# control_module register map
Vendor: Texas Instruments
Registers are 32-bit, access per field, no defined reset value unless marked. A register's access mark holds for its fields unless they carry their own. Offsets are as the file gives them; [hi:lo] are bit positions; 'fields as' and 'values as' point back to an identical list.

## CONTROL_MODULE (part 2 of 3)
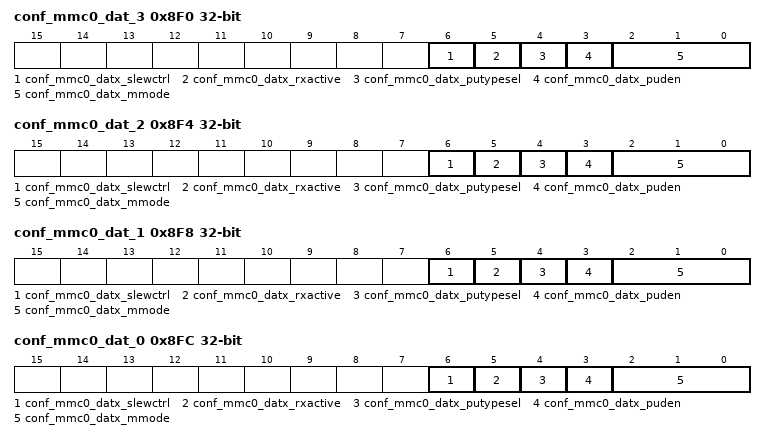
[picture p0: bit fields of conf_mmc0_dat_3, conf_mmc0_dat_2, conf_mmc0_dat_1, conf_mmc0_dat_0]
0x8F0 conf_mmc0_dat_3 — See the device datasheet for information on default pin mux configurations. Note that the device ROM may change the default pin mux for certain pins based on the SYSBOOT mode settings.
  [6] conf_mmc0_datx_slewctrl rw — Select between faster or slower slew rate Reset value is pad-dependent.
    1=en_2_0x1 (Slow); 0=en_1_0x0 (Fast)
  [5] conf_mmc0_datx_rxactive rw — Input enable value for the PAD
    1=en_2_0x1 (Receiver enabled); 0=en_1_0x0 (Receiver disabled)
  [4] conf_mmc0_datx_putypesel rw — Pad pullup/pulldown type selection Reset value is pad-dependent.
    1=en_2_0x1 (Pullup selected); 0=en_1_0x0 (Pulldown selected)
  [3] conf_mmc0_datx_puden rw — Pad pullup/pulldown enable Reset value is pad-dependent.
    1=en_2_0x1 (Pullup/pulldown disabled); 0=en_1_0x0 (Pullup/pulldown enabled)
  [2:0] conf_mmc0_datx_mmode rw — Pad functional signal mux select. Reset value is pad-dependent.
0x8F4 conf_mmc0_dat_2 — See the device datasheet for information on default pin mux configurations. Note that the device ROM may change the default pin mux for certain pins based on the SYSBOOT mode settings.
  fields as conf_mmc0_dat_3
0x8F8 conf_mmc0_dat_1 — See the device datasheet for information on default pin mux configurations. Note that the device ROM may change the default pin mux for certain pins based on the SYSBOOT mode settings.
  fields as conf_mmc0_dat_3
0x8FC conf_mmc0_dat_0 — See the device datasheet for information on default pin mux configurations. Note that the device ROM may change the default pin mux for certain pins based on the SYSBOOT mode settings.
  fields as conf_mmc0_dat_3
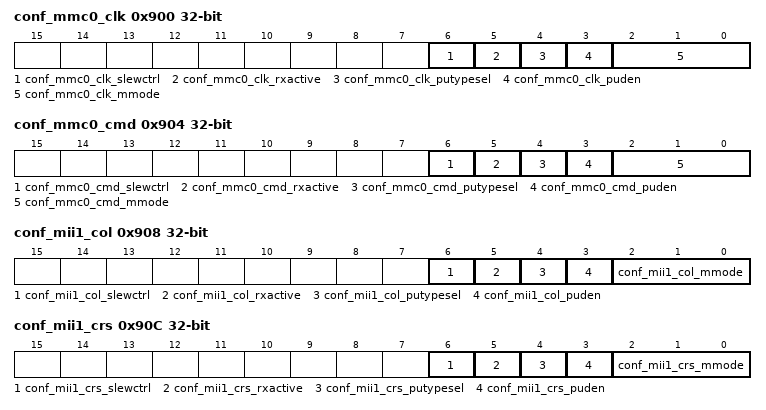
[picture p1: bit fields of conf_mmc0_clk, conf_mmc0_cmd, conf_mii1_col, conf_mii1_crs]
0x900 conf_mmc0_clk — See the device datasheet for information on default pin mux configurations. Note that the device ROM may change the default pin mux for certain pins based on the SYSBOOT mode settings.
  [6] conf_mmc0_clk_slewctrl rw — Select between faster or slower slew rate Reset value is pad-dependent.
    1=en_2_0x1 (Slow); 0=en_1_0x0 (Fast)
  [5] conf_mmc0_clk_rxactive rw — Input enable value for the PAD
    values as conf_mmc0_dat_3.conf_mmc0_datx_rxactive
  [4] conf_mmc0_clk_putypesel rw — Pad pullup/pulldown type selection Reset value is pad-dependent.
    1=en_2_0x1 (Pullup selected); 0=en_1_0x0 (Pulldown selected)
  [3] conf_mmc0_clk_puden rw — Pad pullup/pulldown enable Reset value is pad-dependent.
    values as conf_mmc0_dat_3.conf_mmc0_datx_puden
  [2:0] conf_mmc0_clk_mmode rw — Pad functional signal mux select. Reset value is pad-dependent.
0x904 conf_mmc0_cmd — See the device datasheet for information on default pin mux configurations. Note that the device ROM may change the default pin mux for certain pins based on the SYSBOOT mode settings.
  [6] conf_mmc0_cmd_slewctrl rw — Select between faster or slower slew rate Reset value is pad-dependent.
    1=en_2_0x1 (Slow); 0=en_1_0x0 (Fast)
  [5] conf_mmc0_cmd_rxactive rw — Input enable value for the PAD
    values as conf_mmc0_dat_3.conf_mmc0_datx_rxactive
  [4] conf_mmc0_cmd_putypesel rw — Pad pullup/pulldown type selection Reset value is pad-dependent.
    1=en_2_0x1 (Pullup selected); 0=en_1_0x0 (Pulldown selected)
  [3] conf_mmc0_cmd_puden rw — Pad pullup/pulldown enable Reset value is pad-dependent.
    values as conf_mmc0_dat_3.conf_mmc0_datx_puden
  [2:0] conf_mmc0_cmd_mmode rw — Pad functional signal mux select. Reset value is pad-dependent.
0x908 conf_mii1_col — See the device datasheet for information on default pin mux configurations. Note that the device ROM may change the default pin mux for certain pins based on the SYSBOOT mode settings.
  [6] conf_mii1_col_slewctrl rw — Select between faster or slower slew rate Reset value is pad-dependent.
    1=en_2_0x1 (Slow); 0=en_1_0x0 (Fast)
  [5] conf_mii1_col_rxactive rw — Input enable value for the PAD
    values as conf_mmc0_dat_3.conf_mmc0_datx_rxactive
  [4] conf_mii1_col_putypesel rw — Pad pullup/pulldown type selection Reset value is pad-dependent.
    1=en_2_0x1 (Pullup selected); 0=en_1_0x0 (Pulldown selected)
  [3] conf_mii1_col_puden rw — Pad pullup/pulldown enable Reset value is pad-dependent.
    values as conf_mmc0_dat_3.conf_mmc0_datx_puden
  [2:0] conf_mii1_col_mmode rw — Pad functional signal mux select. Reset value is pad-dependent.
0x90C conf_mii1_crs — See the device datasheet for information on default pin mux configurations. Note that the device ROM may change the default pin mux for certain pins based on the SYSBOOT mode settings.
  [6] conf_mii1_crs_slewctrl rw — Select between faster or slower slew rate Reset value is pad-dependent. Select between faster or slower slew rate Reset value is pad-dependent.
    1=en_2_0x1 (Slow); 0=en_1_0x0 (Fast)
  [5] conf_mii1_crs_rxactive rw — Input enable value for the PAD Input enable value for the PAD
    values as conf_mmc0_dat_3.conf_mmc0_datx_rxactive
  [4] conf_mii1_crs_putypesel rw — Pad pullup/pulldown type selection Reset value is pad-dependent. Pad pullup/pulldown type selection Reset value is pad-dependent.
    1=en_2_0x1 (Pullup selected); 0=en_1_0x0 (Pulldown selected)
  [3] conf_mii1_crs_puden rw — Pad pullup/pulldown enable Reset value is pad-dependent. Pad pullup/pulldown enable Reset value is pad-dependent.
    values as conf_mmc0_dat_3.conf_mmc0_datx_puden
  [2:0] conf_mii1_crs_mmode rw — Pad functional signal mux select. Reset value is pad-dependent. Pad functional signal mux select. Reset value is pad-dependent.
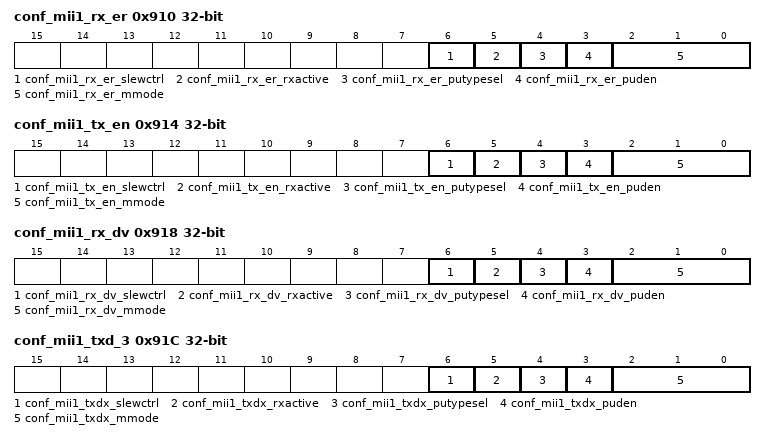
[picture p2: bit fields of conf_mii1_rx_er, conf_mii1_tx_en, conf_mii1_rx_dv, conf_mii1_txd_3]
0x910 conf_mii1_rx_er — See the device datasheet for information on default pin mux configurations. Note that the device ROM may change the default pin mux for certain pins based on the SYSBOOT mode settings.
  [6] conf_mii1_rx_er_slewctrl rw — Select between faster or slower slew rate Reset value is pad-dependent.
    1=en_2_0x1 (Slow); 0=en_1_0x0 (Fast)
  [5] conf_mii1_rx_er_rxactive rw — Input enable value for the PAD
    values as conf_mmc0_dat_3.conf_mmc0_datx_rxactive
  [4] conf_mii1_rx_er_putypesel rw — Pad pullup/pulldown type selection Reset value is pad-dependent.
    1=en_2_0x1 (Pullup selected); 0=en_1_0x0 (Pulldown selected)
  [3] conf_mii1_rx_er_puden rw — Pad pullup/pulldown enable Reset value is pad-dependent.
    values as conf_mmc0_dat_3.conf_mmc0_datx_puden
  [2:0] conf_mii1_rx_er_mmode rw — Pad functional signal mux select. Reset value is pad-dependent.
0x914 conf_mii1_tx_en — See the device datasheet for information on default pin mux configurations. Note that the device ROM may change the default pin mux for certain pins based on the SYSBOOT mode settings.
  [6] conf_mii1_tx_en_slewctrl rw — Select between faster or slower slew rate Reset value is pad-dependent.
    1=en_2_0x1 (Slow); 0=en_1_0x0 (Fast)
  [5] conf_mii1_tx_en_rxactive rw — Input enable value for the PAD
    values as conf_mmc0_dat_3.conf_mmc0_datx_rxactive
  [4] conf_mii1_tx_en_putypesel rw — Pad pullup/pulldown type selection Reset value is pad-dependent.
    1=en_2_0x1 (Pullup selected); 0=en_1_0x0 (Pulldown selected)
  [3] conf_mii1_tx_en_puden rw — Pad pullup/pulldown enable Reset value is pad-dependent.
    values as conf_mmc0_dat_3.conf_mmc0_datx_puden
  [2:0] conf_mii1_tx_en_mmode rw — Pad functional signal mux select. Reset value is pad-dependent.
0x918 conf_mii1_rx_dv — See the device datasheet for information on default pin mux configurations. Note that the device ROM may change the default pin mux for certain pins based on the SYSBOOT mode settings.
  [6] conf_mii1_rx_dv_slewctrl rw — Select between faster or slower slew rate Reset value is pad-dependent.
    1=en_2_0x1 (Slow); 0=en_1_0x0 (Fast)
  [5] conf_mii1_rx_dv_rxactive rw — Input enable value for the PAD
    values as conf_mmc0_dat_3.conf_mmc0_datx_rxactive
  [4] conf_mii1_rx_dv_putypesel rw — Pad pullup/pulldown type selection Reset value is pad-dependent.
    1=en_2_0x1 (Pullup selected); 0=en_1_0x0 (Pulldown selected)
  [3] conf_mii1_rx_dv_puden rw — Pad pullup/pulldown enable Reset value is pad-dependent.
    values as conf_mmc0_dat_3.conf_mmc0_datx_puden
  [2:0] conf_mii1_rx_dv_mmode rw — Pad functional signal mux select. Reset value is pad-dependent.
0x91C conf_mii1_txd_3 — See the device datasheet for information on default pin mux configurations. Note that the device ROM may change the default pin mux for certain pins based on the SYSBOOT mode settings.
  [6] conf_mii1_txdx_slewctrl rw — Select between faster or slower slew rate Reset value is pad-dependent.
    1=en_2_0x1 (Slow); 0=en_1_0x0 (Fast)
  [5] conf_mii1_txdx_rxactive rw — Input enable value for the PAD
    values as conf_mmc0_dat_3.conf_mmc0_datx_rxactive
  [4] conf_mii1_txdx_putypesel rw — Pad pullup/pulldown type selection Reset value is pad-dependent.
    1=en_2_0x1 (Pullup selected); 0=en_1_0x0 (Pulldown selected)
  [3] conf_mii1_txdx_puden rw — Pad pullup/pulldown enable Reset value is pad-dependent.
    values as conf_mmc0_dat_3.conf_mmc0_datx_puden
  [2:0] conf_mii1_txdx_mmode rw — Pad functional signal mux select. Reset value is pad-dependent.
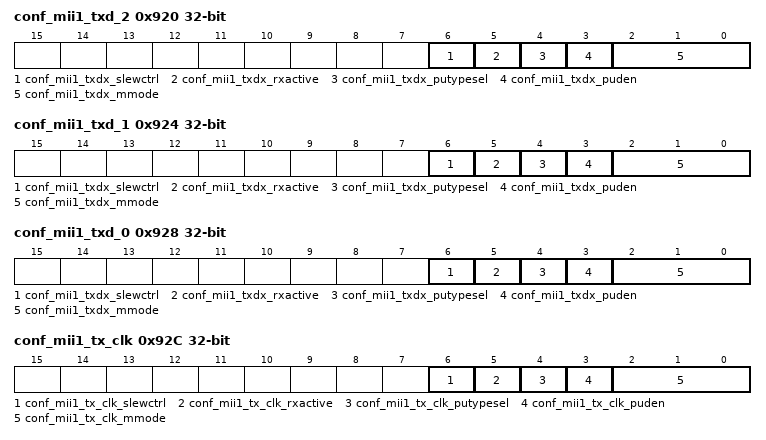
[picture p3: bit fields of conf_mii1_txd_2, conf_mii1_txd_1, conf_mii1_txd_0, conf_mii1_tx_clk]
0x920 conf_mii1_txd_2 — See the device datasheet for information on default pin mux configurations. Note that the device ROM may change the default pin mux for certain pins based on the SYSBOOT mode settings.
  fields as conf_mii1_txd_3
0x924 conf_mii1_txd_1 — See the device datasheet for information on default pin mux configurations. Note that the device ROM may change the default pin mux for certain pins based on the SYSBOOT mode settings.
  fields as conf_mii1_txd_3
0x928 conf_mii1_txd_0 — See the device datasheet for information on default pin mux configurations. Note that the device ROM may change the default pin mux for certain pins based on the SYSBOOT mode settings.
  fields as conf_mii1_txd_3
0x92C conf_mii1_tx_clk — See the device datasheet for information on default pin mux configurations. Note that the device ROM may change the default pin mux for certain pins based on the SYSBOOT mode settings.
  [6] conf_mii1_tx_clk_slewctrl rw — Select between faster or slower slew rate Reset value is pad-dependent.
    1=en_2_0x1 (Slow); 0=en_1_0x0 (Fast)
  [5] conf_mii1_tx_clk_rxactive rw — Input enable value for the PAD
    values as conf_mmc0_dat_3.conf_mmc0_datx_rxactive
  [4] conf_mii1_tx_clk_putypesel rw — Pad pullup/pulldown type selection Reset value is pad-dependent.
    1=en_2_0x1 (Pullup selected); 0=en_1_0x0 (Pulldown selected)
  [3] conf_mii1_tx_clk_puden rw — Pad pullup/pulldown enable Reset value is pad-dependent.
    values as conf_mmc0_dat_3.conf_mmc0_datx_puden
  [2:0] conf_mii1_tx_clk_mmode rw — Pad functional signal mux select. Reset value is pad-dependent.
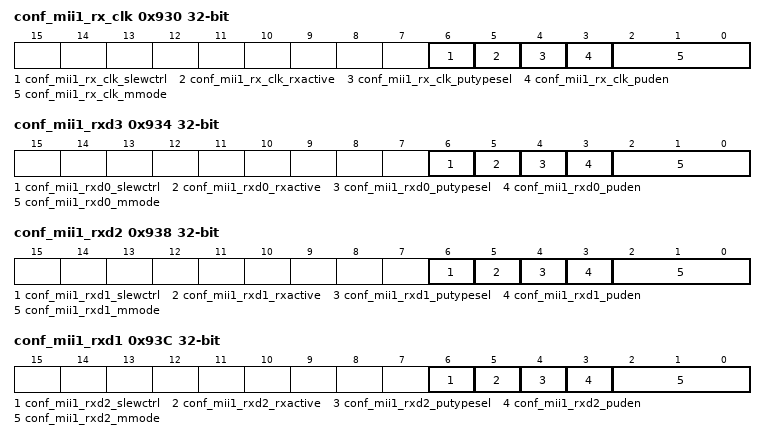
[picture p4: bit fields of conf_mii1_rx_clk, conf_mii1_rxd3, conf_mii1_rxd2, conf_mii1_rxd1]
0x930 conf_mii1_rx_clk — See the device datasheet for information on default pin mux configurations. Note that the device ROM may change the default pin mux for certain pins based on the SYSBOOT mode settings.
  [6] conf_mii1_rx_clk_slewctrl rw — Select between faster or slower slew rate Reset value is pad-dependent.
    1=en_2_0x1 (Slow); 0=en_1_0x0 (Fast)
  [5] conf_mii1_rx_clk_rxactive rw — Input enable value for the PAD
    values as conf_mmc0_dat_3.conf_mmc0_datx_rxactive
  [4] conf_mii1_rx_clk_putypesel rw — Pad pullup/pulldown type selection Reset value is pad-dependent.
    1=en_2_0x1 (Pullup selected); 0=en_1_0x0 (Pulldown selected)
  [3] conf_mii1_rx_clk_puden rw — Pad pullup/pulldown enable Reset value is pad-dependent.
    values as conf_mmc0_dat_3.conf_mmc0_datx_puden
  [2:0] conf_mii1_rx_clk_mmode rw — Pad functional signal mux select. Reset value is pad-dependent.
0x934 conf_mii1_rxd3 — See the device datasheet for information on default pin mux configurations. Note that the device ROM may change the default pin mux for certain pins based on the SYSBOOT mode settings.
  [6] conf_mii1_rxd0_slewctrl rw — Select between faster or slower slew rate Reset value is pad-dependent.
    1=en_2_0x1 (Slow); 0=en_1_0x0 (Fast)
  [5] conf_mii1_rxd0_rxactive rw — Input enable value for the PAD
    values as conf_mmc0_dat_3.conf_mmc0_datx_rxactive
  [4] conf_mii1_rxd0_putypesel rw — Pad pullup/pulldown type selection Reset value is pad-dependent.
    1=en_2_0x1 (Pullup selected); 0=en_1_0x0 (Pulldown selected)
  [3] conf_mii1_rxd0_puden rw — Pad pullup/pulldown enable Reset value is pad-dependent.
    values as conf_mmc0_dat_3.conf_mmc0_datx_puden
  [2:0] conf_mii1_rxd0_mmode rw — Pad functional signal mux select. Reset value is pad-dependent.
0x938 conf_mii1_rxd2 — See the device datasheet for information on default pin mux configurations. Note that the device ROM may change the default pin mux for certain pins based on the SYSBOOT mode settings.
  [6] conf_mii1_rxd1_slewctrl rw — Select between faster or slower slew rate Reset value is pad-dependent.
    1=en_2_0x1 (Slow); 0=en_1_0x0 (Fast)
  [5] conf_mii1_rxd1_rxactive rw — Input enable value for the PAD
    values as conf_mmc0_dat_3.conf_mmc0_datx_rxactive
  [4] conf_mii1_rxd1_putypesel rw — Pad pullup/pulldown type selection Reset value is pad-dependent.
    1=en_2_0x1 (Pullup selected); 0=en_1_0x0 (Pulldown selected)
  [3] conf_mii1_rxd1_puden rw — Pad pullup/pulldown enable Reset value is pad-dependent.
    values as conf_mmc0_dat_3.conf_mmc0_datx_puden
  [2:0] conf_mii1_rxd1_mmode rw — Pad functional signal mux select. Reset value is pad-dependent.
0x93C conf_mii1_rxd1 — See the device datasheet for information on default pin mux configurations. Note that the device ROM may change the default pin mux for certain pins based on the SYSBOOT mode settings.
  [6] conf_mii1_rxd2_slewctrl rw — Select between faster or slower slew rate Reset value is pad-dependent.
    1=en_2_0x1 (Slow); 0=en_1_0x0 (Fast)
  [5] conf_mii1_rxd2_rxactive rw — Input enable value for the PAD
    values as conf_mmc0_dat_3.conf_mmc0_datx_rxactive
  [4] conf_mii1_rxd2_putypesel rw — Pad pullup/pulldown type selection Reset value is pad-dependent.
    1=en_2_0x1 (Pullup selected); 0=en_1_0x0 (Pulldown selected)
  [3] conf_mii1_rxd2_puden rw — Pad pullup/pulldown enable Reset value is pad-dependent.
    values as conf_mmc0_dat_3.conf_mmc0_datx_puden
  [2:0] conf_mii1_rxd2_mmode rw — Pad functional signal mux select. Reset value is pad-dependent.
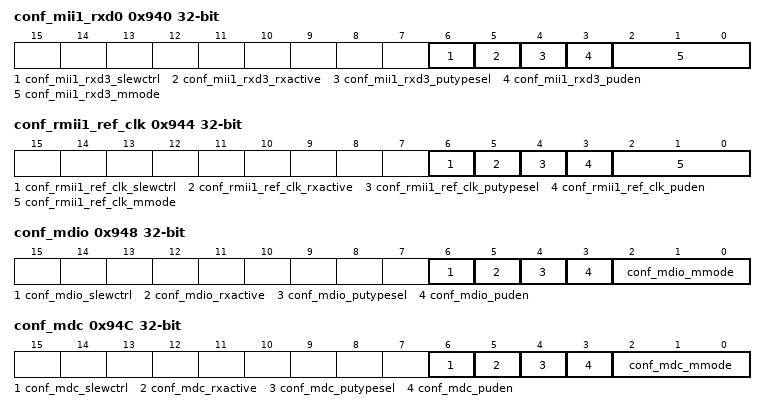
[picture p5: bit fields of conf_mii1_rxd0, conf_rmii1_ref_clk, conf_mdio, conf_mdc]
0x940 conf_mii1_rxd0 — See the device datasheet for information on default pin mux configurations. Note that the device ROM may change the default pin mux for certain pins based on the SYSBOOT mode settings.
  [6] conf_mii1_rxd3_slewctrl rw — Select between faster or slower slew rate Reset value is pad-dependent.
    1=en_2_0x1 (Slow); 0=en_1_0x0 (Fast)
  [5] conf_mii1_rxd3_rxactive rw — Input enable value for the PAD
    values as conf_mmc0_dat_3.conf_mmc0_datx_rxactive
  [4] conf_mii1_rxd3_putypesel rw — Pad pullup/pulldown type selection Reset value is pad-dependent.
    1=en_2_0x1 (Pullup selected); 0=en_1_0x0 (Pulldown selected)
  [3] conf_mii1_rxd3_puden rw — Pad pullup/pulldown enable Reset value is pad-dependent.
    values as conf_mmc0_dat_3.conf_mmc0_datx_puden
  [2:0] conf_mii1_rxd3_mmode rw — Pad functional signal mux select. Reset value is pad-dependent.
0x944 conf_rmii1_ref_clk — See the device datasheet for information on default pin mux configurations. Note that the device ROM may change the default pin mux for certain pins based on the SYSBOOT mode settings.
  [6] conf_rmii1_ref_clk_slewctrl rw — Select between faster or slower slew rate Reset value is pad-dependent.
    1=en_2_0x1 (Slow); 0=en_1_0x0 (Fast)
  [5] conf_rmii1_ref_clk_rxactive rw — Input enable value for the PAD
    values as conf_mmc0_dat_3.conf_mmc0_datx_rxactive
  [4] conf_rmii1_ref_clk_putypesel rw — Pad pullup/pulldown type selection Reset value is pad-dependent.
    1=en_2_0x1 (Pullup selected); 0=en_1_0x0 (Pulldown selected)
  [3] conf_rmii1_ref_clk_puden rw — Pad pullup/pulldown enable Reset value is pad-dependent.
    values as conf_mmc0_dat_3.conf_mmc0_datx_puden
  [2:0] conf_rmii1_ref_clk_mmode rw — Pad functional signal mux select. Reset value is pad-dependent.
0x948 conf_mdio — See the device datasheet for information on default pin mux configurations. Note that the device ROM may change the default pin mux for certain pins based on the SYSBOOT mode settings.
  [6] conf_mdio_slewctrl rw — Select between faster or slower slew rate Reset value is pad-dependent.
    1=en_2_0x1 (Slow); 0=en_1_0x0 (Fast)
  [5] conf_mdio_rxactive rw — Input enable value for the PAD
    values as conf_mmc0_dat_3.conf_mmc0_datx_rxactive
  [4] conf_mdio_putypesel rw — Pad pullup/pulldown type selection Reset value is pad-dependent.
    1=en_2_0x1 (Pullup selected); 0=en_1_0x0 (Pulldown selected)
  [3] conf_mdio_puden rw — Pad pullup/pulldown enable Reset value is pad-dependent.
    values as conf_mmc0_dat_3.conf_mmc0_datx_puden
  [2:0] conf_mdio_mmode rw — Pad functional signal mux select. Reset value is pad-dependent.
0x94C conf_mdc — See the device datasheet for information on default pin mux configurations. Note that the device ROM may change the default pin mux for certain pins based on the SYSBOOT mode settings.
  [6] conf_mdc_slewctrl rw — Select between faster or slower slew rate Reset value is pad-dependent.
    1=en_2_0x1 (Slow); 0=en_1_0x0 (Fast)
  [5] conf_mdc_rxactive rw — Input enable value for the PAD
    values as conf_mmc0_dat_3.conf_mmc0_datx_rxactive
  [4] conf_mdc_putypesel rw — Pad pullup/pulldown type selection Reset value is pad-dependent.
    1=en_2_0x1 (Pullup selected); 0=en_1_0x0 (Pulldown selected)
  [3] conf_mdc_puden rw — Pad pullup/pulldown enable Reset value is pad-dependent.
    values as conf_mmc0_dat_3.conf_mmc0_datx_puden
  [2:0] conf_mdc_mmode rw — Pad functional signal mux select. Reset value is pad-dependent.
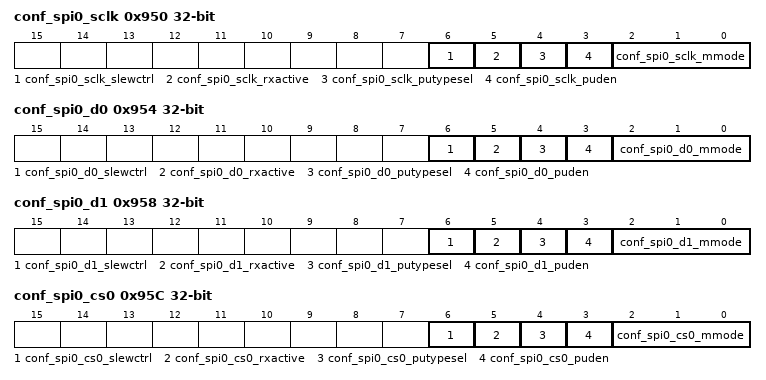
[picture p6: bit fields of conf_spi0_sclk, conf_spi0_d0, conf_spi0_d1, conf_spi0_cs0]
0x950 conf_spi0_sclk — See the device datasheet for information on default pin mux configurations. Note that the device ROM may change the default pin mux for certain pins based on the SYSBOOT mode settings.
  [6] conf_spi0_sclk_slewctrl rw — Select between faster or slower slew rate Reset value is pad-dependent.
    1=en_2_0x1 (Slow); 0=en_1_0x0 (Fast)
  [5] conf_spi0_sclk_rxactive rw — Input enable value for the PAD
    values as conf_mmc0_dat_3.conf_mmc0_datx_rxactive
  [4] conf_spi0_sclk_putypesel rw — Pad pullup/pulldown type selection Reset value is pad-dependent.
    1=en_2_0x1 (Pullup selected); 0=en_1_0x0 (Pulldown selected)
  [3] conf_spi0_sclk_puden rw — Pad pullup/pulldown enable Reset value is pad-dependent.
    values as conf_mmc0_dat_3.conf_mmc0_datx_puden
  [2:0] conf_spi0_sclk_mmode rw — Pad functional signal mux select. Reset value is pad-dependent.
0x954 conf_spi0_d0 — See the device datasheet for information on default pin mux configurations. Note that the device ROM may change the default pin mux for certain pins based on the SYSBOOT mode settings.
  [6] conf_spi0_d0_slewctrl rw — Select between faster or slower slew rate Reset value is pad-dependent.
    1=en_2_0x1 (Slow); 0=en_1_0x0 (Fast)
  [5] conf_spi0_d0_rxactive rw — Input enable value for the PAD
    values as conf_mmc0_dat_3.conf_mmc0_datx_rxactive
  [4] conf_spi0_d0_putypesel rw — Pad pullup/pulldown type selection Reset value is pad-dependent.
    1=en_2_0x1 (Pullup selected); 0=en_1_0x0 (Pulldown selected)
  [3] conf_spi0_d0_puden rw — Pad pullup/pulldown enable Reset value is pad-dependent.
    values as conf_mmc0_dat_3.conf_mmc0_datx_puden
  [2:0] conf_spi0_d0_mmode rw — Pad functional signal mux select. Reset value is pad-dependent.
0x958 conf_spi0_d1 — See the device datasheet for information on default pin mux configurations. Note that the device ROM may change the default pin mux for certain pins based on the SYSBOOT mode settings.
  [6] conf_spi0_d1_slewctrl rw — Select between faster or slower slew rate Reset value is pad-dependent.
    1=en_2_0x1 (Slow); 0=en_1_0x0 (Fast)
  [5] conf_spi0_d1_rxactive rw — Input enable value for the PAD
    values as conf_mmc0_dat_3.conf_mmc0_datx_rxactive
  [4] conf_spi0_d1_putypesel rw — Pad pullup/pulldown type selection Reset value is pad-dependent.
    1=en_2_0x1 (Pullup selected); 0=en_1_0x0 (Pulldown selected)
  [3] conf_spi0_d1_puden rw — Pad pullup/pulldown enable Reset value is pad-dependent.
    values as conf_mmc0_dat_3.conf_mmc0_datx_puden
  [2:0] conf_spi0_d1_mmode rw — Pad functional signal mux select. Reset value is pad-dependent.
0x95C conf_spi0_cs0 — See the device datasheet for information on default pin mux configurations. Note that the device ROM may change the default pin mux for certain pins based on the SYSBOOT mode settings.
  [6] conf_spi0_cs0_slewctrl rw — Select between faster or slower slew rate Reset value is pad-dependent.
    1=en_2_0x1 (Slow); 0=en_1_0x0 (Fast)
  [5] conf_spi0_cs0_rxactive rw — Input enable value for the PAD
    values as conf_mmc0_dat_3.conf_mmc0_datx_rxactive
  [4] conf_spi0_cs0_putypesel rw — Pad pullup/pulldown type selection Reset value is pad-dependent.
    1=en_2_0x1 (Pullup selected); 0=en_1_0x0 (Pulldown selected)
  [3] conf_spi0_cs0_puden rw — Pad pullup/pulldown enable Reset value is pad-dependent.
    values as conf_mmc0_dat_3.conf_mmc0_datx_puden
  [2:0] conf_spi0_cs0_mmode rw — Pad functional signal mux select. Reset value is pad-dependent.
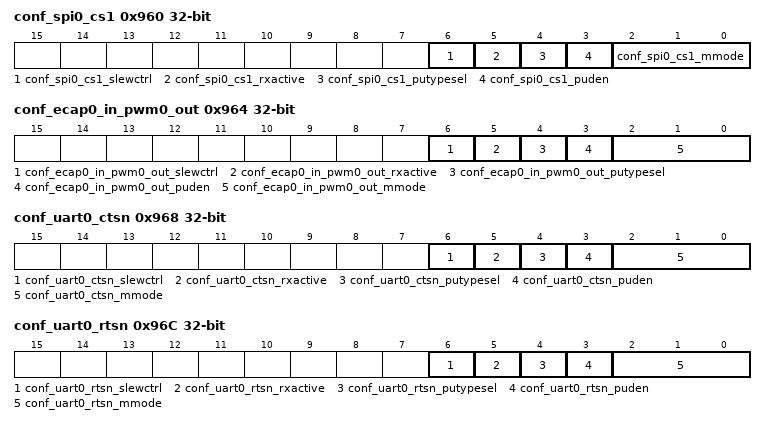
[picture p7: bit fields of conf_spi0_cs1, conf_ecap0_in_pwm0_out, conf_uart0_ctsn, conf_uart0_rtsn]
0x960 conf_spi0_cs1 — See the device datasheet for information on default pin mux configurations. Note that the device ROM may change the default pin mux for certain pins based on the SYSBOOT mode settings.
  [6] conf_spi0_cs1_slewctrl rw — Select between faster or slower slew rate Reset value is pad-dependent.
    1=en_2_0x1 (Slow); 0=en_1_0x0 (Fast)
  [5] conf_spi0_cs1_rxactive rw — Input enable value for the PAD
    values as conf_mmc0_dat_3.conf_mmc0_datx_rxactive
  [4] conf_spi0_cs1_putypesel rw — Pad pullup/pulldown type selection Reset value is pad-dependent.
    1=en_2_0x1 (Pullup selected); 0=en_1_0x0 (Pulldown selected)
  [3] conf_spi0_cs1_puden rw — Pad pullup/pulldown enable Reset value is pad-dependent.
    values as conf_mmc0_dat_3.conf_mmc0_datx_puden
  [2:0] conf_spi0_cs1_mmode rw — Pad functional signal mux select. Reset value is pad-dependent.
0x964 conf_ecap0_in_pwm0_out — See the device datasheet for information on default pin mux configurations. Note that the device ROM may change the default pin mux for certain pins based on the SYSBOOT mode settings.
  [6] conf_ecap0_in_pwm0_out_slewctrl rw — Select between faster or slower slew rate Reset value is pad-dependent.
    1=en_2_0x1 (Slow); 0=en_1_0x0 (Fast)
  [5] conf_ecap0_in_pwm0_out_rxactive rw — Input enable value for the PAD
    values as conf_mmc0_dat_3.conf_mmc0_datx_rxactive
  [4] conf_ecap0_in_pwm0_out_putypesel rw — Pad pullup/pulldown type selection Reset value is pad-dependent.
    1=en_2_0x1 (Pullup selected); 0=en_1_0x0 (Pulldown selected)
  [3] conf_ecap0_in_pwm0_out_puden rw — Pad pullup/pulldown enable Reset value is pad-dependent.
    values as conf_mmc0_dat_3.conf_mmc0_datx_puden
  [2:0] conf_ecap0_in_pwm0_out_mmode rw — Pad functional signal mux select. Reset value is pad-dependent.
0x968 conf_uart0_ctsn — See the device datasheet for information on default pin mux configurations. Note that the device ROM may change the default pin mux for certain pins based on the SYSBOOT mode settings.
  [6] conf_uart0_ctsn_slewctrl rw — Select between faster or slower slew rate Reset value is pad-dependent.
    1=en_2_0x1 (Slow); 0=en_1_0x0 (Fast)
  [5] conf_uart0_ctsn_rxactive rw — Input enable value for the PAD
    values as conf_mmc0_dat_3.conf_mmc0_datx_rxactive
  [4] conf_uart0_ctsn_putypesel rw — Pad pullup/pulldown type selection Reset value is pad-dependent.
    1=en_2_0x1 (Pullup selected); 0=en_1_0x0 (Pulldown selected)
  [3] conf_uart0_ctsn_puden rw — Pad pullup/pulldown enable Reset value is pad-dependent.
    values as conf_mmc0_dat_3.conf_mmc0_datx_puden
  [2:0] conf_uart0_ctsn_mmode rw — Pad functional signal mux select. Reset value is pad-dependent.
0x96C conf_uart0_rtsn — See the device datasheet for information on default pin mux configurations. Note that the device ROM may change the default pin mux for certain pins based on the SYSBOOT mode settings.
  [6] conf_uart0_rtsn_slewctrl rw — Select between faster or slower slew rate Reset value is pad-dependent.
    1=en_2_0x1 (Slow); 0=en_1_0x0 (Fast)
  [5] conf_uart0_rtsn_rxactive rw — Input enable value for the PAD
    values as conf_mmc0_dat_3.conf_mmc0_datx_rxactive
  [4] conf_uart0_rtsn_putypesel rw — Pad pullup/pulldown type selection Reset value is pad-dependent.
    1=en_2_0x1 (Pullup selected); 0=en_1_0x0 (Pulldown selected)
  [3] conf_uart0_rtsn_puden rw — Pad pullup/pulldown enable Reset value is pad-dependent.
    values as conf_mmc0_dat_3.conf_mmc0_datx_puden
  [2:0] conf_uart0_rtsn_mmode rw — Pad functional signal mux select. Reset value is pad-dependent.
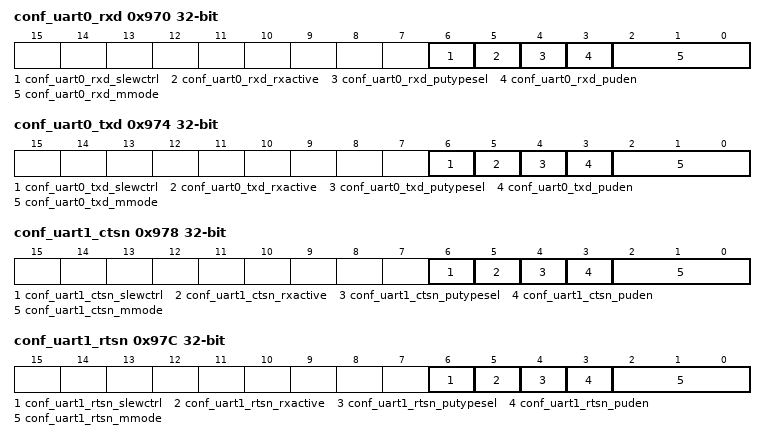
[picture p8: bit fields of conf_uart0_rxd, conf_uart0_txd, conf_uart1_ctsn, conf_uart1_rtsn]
0x970 conf_uart0_rxd — See the device datasheet for information on default pin mux configurations. Note that the device ROM may change the default pin mux for certain pins based on the SYSBOOT mode settings.
  [6] conf_uart0_rxd_slewctrl rw — Select between faster or slower slew rate Reset value is pad-dependent.
    1=en_2_0x1 (Slow); 0=en_1_0x0 (Fast)
  [5] conf_uart0_rxd_rxactive rw — Input enable value for the PAD
    values as conf_mmc0_dat_3.conf_mmc0_datx_rxactive
  [4] conf_uart0_rxd_putypesel rw — Pad pullup/pulldown type selection Reset value is pad-dependent.
    1=en_2_0x1 (Pullup selected); 0=en_1_0x0 (Pulldown selected)
  [3] conf_uart0_rxd_puden rw — Pad pullup/pulldown enable Reset value is pad-dependent.
    values as conf_mmc0_dat_3.conf_mmc0_datx_puden
  [2:0] conf_uart0_rxd_mmode rw — Pad functional signal mux select. Reset value is pad-dependent.
0x974 conf_uart0_txd — See the device datasheet for information on default pin mux configurations. Note that the device ROM may change the default pin mux for certain pins based on the SYSBOOT mode settings.
  [6] conf_uart0_txd_slewctrl rw — Select between faster or slower slew rate Reset value is pad-dependent.
    1=en_2_0x1 (Slow); 0=en_1_0x0 (Fast)
  [5] conf_uart0_txd_rxactive rw — Input enable value for the PAD
    values as conf_mmc0_dat_3.conf_mmc0_datx_rxactive
  [4] conf_uart0_txd_putypesel rw — Pad pullup/pulldown type selection Reset value is pad-dependent.
    1=en_2_0x1 (Pullup selected); 0=en_1_0x0 (Pulldown selected)
  [3] conf_uart0_txd_puden rw — Pad pullup/pulldown enable Reset value is pad-dependent.
    values as conf_mmc0_dat_3.conf_mmc0_datx_puden
  [2:0] conf_uart0_txd_mmode rw — Pad functional signal mux select. Reset value is pad-dependent.
0x978 conf_uart1_ctsn — See the device datasheet for information on default pin mux configurations. Note that the device ROM may change the default pin mux for certain pins based on the SYSBOOT mode settings.
  [6] conf_uart1_ctsn_slewctrl rw — Select between faster or slower slew rate Reset value is pad-dependent.
    1=en_2_0x1 (Slow); 0=en_1_0x0 (Fast)
  [5] conf_uart1_ctsn_rxactive rw — Input enable value for the PAD
    values as conf_mmc0_dat_3.conf_mmc0_datx_rxactive
  [4] conf_uart1_ctsn_putypesel rw — Pad pullup/pulldown type selection Reset value is pad-dependent.
    1=en_2_0x1 (Pullup selected); 0=en_1_0x0 (Pulldown selected)
  [3] conf_uart1_ctsn_puden rw — Pad pullup/pulldown enable Reset value is pad-dependent.
    values as conf_mmc0_dat_3.conf_mmc0_datx_puden
  [2:0] conf_uart1_ctsn_mmode rw — Pad functional signal mux select. Reset value is pad-dependent.
0x97C conf_uart1_rtsn — See the device datasheet for information on default pin mux configurations. Note that the device ROM may change the default pin mux for certain pins based on the SYSBOOT mode settings.
  [6] conf_uart1_rtsn_slewctrl rw — Select between faster or slower slew rate Reset value is pad-dependent.
    1=en_2_0x1 (Slow); 0=en_1_0x0 (Fast)
  [5] conf_uart1_rtsn_rxactive rw — Input enable value for the PAD
    values as conf_mmc0_dat_3.conf_mmc0_datx_rxactive
  [4] conf_uart1_rtsn_putypesel rw — Pad pullup/pulldown type selection Reset value is pad-dependent.
    1=en_2_0x1 (Pullup selected); 0=en_1_0x0 (Pulldown selected)
  [3] conf_uart1_rtsn_puden rw — Pad pullup/pulldown enable Reset value is pad-dependent.
    values as conf_mmc0_dat_3.conf_mmc0_datx_puden
  [2:0] conf_uart1_rtsn_mmode rw — Pad functional signal mux select. Reset value is pad-dependent.
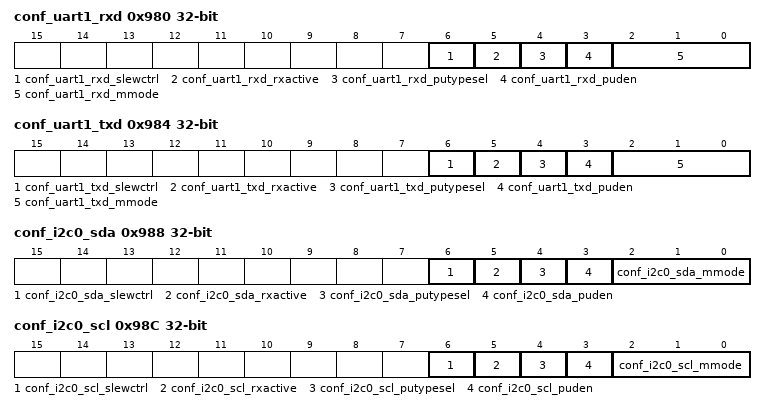
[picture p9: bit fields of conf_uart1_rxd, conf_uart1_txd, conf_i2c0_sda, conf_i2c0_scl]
0x980 conf_uart1_rxd — See the device datasheet for information on default pin mux configurations. Note that the device ROM may change the default pin mux for certain pins based on the SYSBOOT mode settings.
  [6] conf_uart1_rxd_slewctrl rw — Select between faster or slower slew rate Reset value is pad-dependent.
    1=en_2_0x1 (Slow); 0=en_1_0x0 (Fast)
  [5] conf_uart1_rxd_rxactive rw — Input enable value for the PAD
    values as conf_mmc0_dat_3.conf_mmc0_datx_rxactive
  [4] conf_uart1_rxd_putypesel rw — Pad pullup/pulldown type selection Reset value is pad-dependent.
    1=en_2_0x1 (Pullup selected); 0=en_1_0x0 (Pulldown selected)
  [3] conf_uart1_rxd_puden rw — Pad pullup/pulldown enable Reset value is pad-dependent.
    values as conf_mmc0_dat_3.conf_mmc0_datx_puden
  [2:0] conf_uart1_rxd_mmode rw — Pad functional signal mux select. Reset value is pad-dependent.
0x984 conf_uart1_txd — See the device datasheet for information on default pin mux configurations. Note that the device ROM may change the default pin mux for certain pins based on the SYSBOOT mode settings.
  [6] conf_uart1_txd_slewctrl rw — Select between faster or slower slew rate Reset value is pad-dependent.
    1=en_2_0x1 (Slow); 0=en_1_0x0 (Fast)
  [5] conf_uart1_txd_rxactive rw — Input enable value for the PAD
    values as conf_mmc0_dat_3.conf_mmc0_datx_rxactive
  [4] conf_uart1_txd_putypesel rw — Pad pullup/pulldown type selection Reset value is pad-dependent.
    1=en_2_0x1 (Pullup selected); 0=en_1_0x0 (Pulldown selected)
  [3] conf_uart1_txd_puden rw — Pad pullup/pulldown enable Reset value is pad-dependent.
    values as conf_mmc0_dat_3.conf_mmc0_datx_puden
  [2:0] conf_uart1_txd_mmode rw — Pad functional signal mux select. Reset value is pad-dependent.
0x988 conf_i2c0_sda — See the device datasheet for information on default pin mux configurations. Note that the device ROM may change the default pin mux for certain pins based on the SYSBOOT mode settings.
  [6] conf_i2c0_sda_slewctrl rw — Select between faster or slower slew rate Reset value is pad-dependent.
    1=en_2_0x1 (Slow); 0=en_1_0x0 (Fast)
  [5] conf_i2c0_sda_rxactive rw — Input enable value for the PAD
    values as conf_mmc0_dat_3.conf_mmc0_datx_rxactive
  [4] conf_i2c0_sda_putypesel rw — Pad pullup/pulldown type selection Reset value is pad-dependent.
    1=en_2_0x1 (Pullup selected); 0=en_1_0x0 (Pulldown selected)
  [3] conf_i2c0_sda_puden rw — Pad pullup/pulldown enable Reset value is pad-dependent.
    values as conf_mmc0_dat_3.conf_mmc0_datx_puden
  [2:0] conf_i2c0_sda_mmode rw — Pad functional signal mux select. Reset value is pad-dependent.
0x98C conf_i2c0_scl — See the device datasheet for information on default pin mux configurations. Note that the device ROM may change the default pin mux for certain pins based on the SYSBOOT mode settings.
  [6] conf_i2c0_scl_slewctrl rw — Select between faster or slower slew rate Reset value is pad-dependent.
    1=en_2_0x1 (Slow); 0=en_1_0x0 (Fast)
  [5] conf_i2c0_scl_rxactive rw — Input enable value for the PAD
    values as conf_mmc0_dat_3.conf_mmc0_datx_rxactive
  [4] conf_i2c0_scl_putypesel rw — Pad pullup/pulldown type selection Reset value is pad-dependent.
    1=en_2_0x1 (Pullup selected); 0=en_1_0x0 (Pulldown selected)
  [3] conf_i2c0_scl_puden rw — Pad pullup/pulldown enable Reset value is pad-dependent.
    values as conf_mmc0_dat_3.conf_mmc0_datx_puden
  [2:0] conf_i2c0_scl_mmode rw — Pad functional signal mux select. Reset value is pad-dependent.
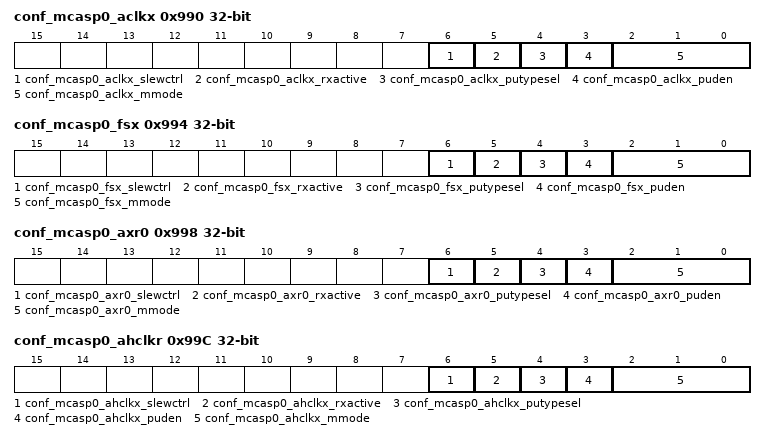
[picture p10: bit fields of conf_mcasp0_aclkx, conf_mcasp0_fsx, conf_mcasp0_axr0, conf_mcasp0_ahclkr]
0x990 conf_mcasp0_aclkx — See the device datasheet for information on default pin mux configurations. Note that the device ROM may change the default pin mux for certain pins based on the SYSBOOT mode settings.
  [6] conf_mcasp0_aclkx_slewctrl rw — Select between faster or slower slew rate Reset value is pad-dependent.
    1=en_2_0x1 (Slow); 0=en_1_0x0 (Fast)
  [5] conf_mcasp0_aclkx_rxactive rw — Input enable value for the PAD
    values as conf_mmc0_dat_3.conf_mmc0_datx_rxactive
  [4] conf_mcasp0_aclkx_putypesel rw — Pad pullup/pulldown type selection Reset value is pad-dependent.
    1=en_2_0x1 (Pullup selected); 0=en_1_0x0 (Pulldown selected)
  [3] conf_mcasp0_aclkx_puden rw — Pad pullup/pulldown enable Reset value is pad-dependent.
    values as conf_mmc0_dat_3.conf_mmc0_datx_puden
  [2:0] conf_mcasp0_aclkx_mmode rw — Pad functional signal mux select. Reset value is pad-dependent.
0x994 conf_mcasp0_fsx — See the device datasheet for information on default pin mux configurations. Note that the device ROM may change the default pin mux for certain pins based on the SYSBOOT mode settings.
  [6] conf_mcasp0_fsx_slewctrl rw — Select between faster or slower slew rate Reset value is pad-dependent.
    1=en_2_0x1 (Slow); 0=en_1_0x0 (Fast)
  [5] conf_mcasp0_fsx_rxactive rw — Input enable value for the PAD
    values as conf_mmc0_dat_3.conf_mmc0_datx_rxactive
  [4] conf_mcasp0_fsx_putypesel rw — Pad pullup/pulldown type selection Reset value is pad-dependent.
    1=en_2_0x1 (Pullup selected); 0=en_1_0x0 (Pulldown selected)
  [3] conf_mcasp0_fsx_puden rw — Pad pullup/pulldown enable Reset value is pad-dependent.
    values as conf_mmc0_dat_3.conf_mmc0_datx_puden
  [2:0] conf_mcasp0_fsx_mmode rw — Pad functional signal mux select. Reset value is pad-dependent.
0x998 conf_mcasp0_axr0 — See the device datasheet for information on default pin mux configurations. Note that the device ROM may change the default pin mux for certain pins based on the SYSBOOT mode settings.
  [6] conf_mcasp0_axr0_slewctrl rw — Select between faster or slower slew rate Reset value is pad-dependent.
    1=en_2_0x1 (Slow); 0=en_1_0x0 (Fast)
  [5] conf_mcasp0_axr0_rxactive rw — Input enable value for the PAD
    values as conf_mmc0_dat_3.conf_mmc0_datx_rxactive
  [4] conf_mcasp0_axr0_putypesel rw — Pad pullup/pulldown type selection Reset value is pad-dependent.
    1=en_2_0x1 (Pullup selected); 0=en_1_0x0 (Pulldown selected)
  [3] conf_mcasp0_axr0_puden rw — Pad pullup/pulldown enable Reset value is pad-dependent.
    values as conf_mmc0_dat_3.conf_mmc0_datx_puden
  [2:0] conf_mcasp0_axr0_mmode rw — Pad functional signal mux select. Reset value is pad-dependent.
0x99C conf_mcasp0_ahclkr — See the device datasheet for information on default pin mux configurations. Note that the device ROM may change the default pin mux for certain pins based on the SYSBOOT mode settings.
  [6] conf_mcasp0_ahclkx_slewctrl rw — Select between faster or slower slew rate Reset value is pad-dependent.
    1=en_2_0x1 (Slow); 0=en_1_0x0 (Fast)
  [5] conf_mcasp0_ahclkx_rxactive rw — Input enable value for the PAD
    values as conf_mmc0_dat_3.conf_mmc0_datx_rxactive
  [4] conf_mcasp0_ahclkx_putypesel rw — Pad pullup/pulldown type selection Reset value is pad-dependent.
    1=en_2_0x1 (Pullup selected); 0=en_1_0x0 (Pulldown selected)
  [3] conf_mcasp0_ahclkx_puden rw — Pad pullup/pulldown enable Reset value is pad-dependent.
    values as conf_mmc0_dat_3.conf_mmc0_datx_puden
  [2:0] conf_mcasp0_ahclkx_mmode rw — Pad functional signal mux select. Reset value is pad-dependent.
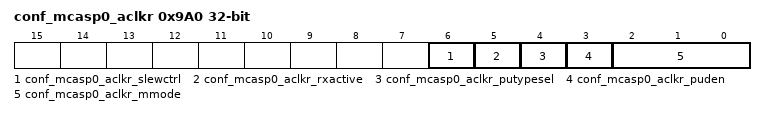
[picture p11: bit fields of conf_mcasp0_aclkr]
0x9A0 conf_mcasp0_aclkr — See the device datasheet for information on default pin mux configurations. Note that the device ROM may change the default pin mux for certain pins based on the SYSBOOT mode settings.
  [6] conf_mcasp0_aclkr_slewctrl rw — Select between faster or slower slew rate Reset value is pad-dependent.
    1=en_2_0x1 (Slow); 0=en_1_0x0 (Fast)
  [5] conf_mcasp0_aclkr_rxactive rw — Input enable value for the PAD
    values as conf_mmc0_dat_3.conf_mmc0_datx_rxactive
  [4] conf_mcasp0_aclkr_putypesel rw — Pad pullup/pulldown type selection Reset value is pad-dependent.
    1=en_2_0x1 (Pullup selected); 0=en_1_0x0 (Pulldown selected)
  [3] conf_mcasp0_aclkr_puden rw — Pad pullup/pulldown enable Reset value is pad-dependent.
    values as conf_mmc0_dat_3.conf_mmc0_datx_puden
  [2:0] conf_mcasp0_aclkr_mmode rw — Pad functional signal mux select. Reset value is pad-dependent.
